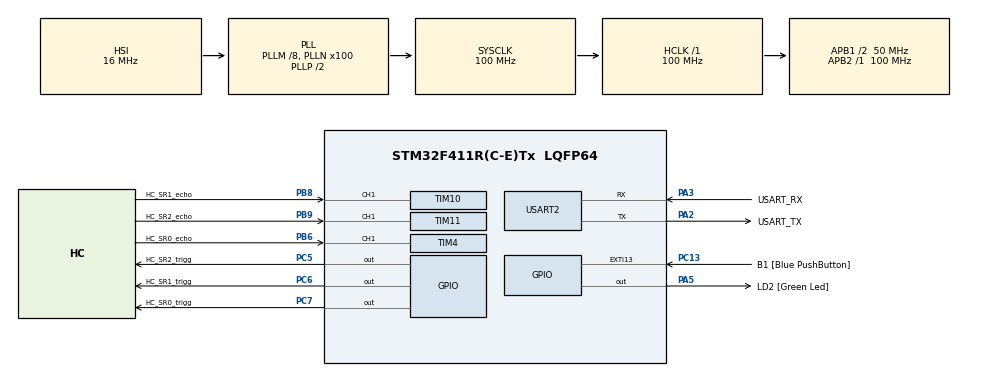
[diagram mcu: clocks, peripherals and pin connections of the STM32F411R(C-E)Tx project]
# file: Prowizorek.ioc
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Mcu.Family=STM32F4
Mcu.Name=STM32F411R(C-E)Tx
Mcu.Package=LQFP64
NVIC.PriorityGroup=NVIC_PRIORITYGROUP_0
PA13.GPIO_Label=TMS
PA13.Signal=SYS_JTMS-SWDIO
PA14.GPIO_Label=TCK
PA14.Signal=SYS_JTCK-SWCLK
PA2.GPIO_Label=USART_TX
PA2.Mode=Asynchronous
PA2.Signal=USART2_TX
PA3.GPIO_Label=USART_RX
PA3.Mode=Asynchronous
PA3.Signal=USART2_RX
PA5.GPIO_Label=LD2 [Green Led]
PA5.Signal=GPIO_Output
PB3.GPIO_Label=SWO
PB3.Signal=SYS_JTDO-SWO
PB6.GPIO_Label=HC_SR0_echo
PB6.Signal=S_TIM4_CH1
PB8.GPIO_Label=HC_SR1_echo
PB8.Signal=S_TIM10_CH1
PB9.GPIO_Label=HC_SR2_echo
PB9.Signal=S_TIM11_CH1
PC13-ANTI_TAMP.GPIO_Label=B1 [Blue PushButton]
PC13-ANTI_TAMP.GPIO_ModeDefaultEXTI=GPIO_MODE_EVT_RISING
PC13-ANTI_TAMP.Signal=GPXTI13
PC14-OSC32_IN.Signal=RCC_OSC32_IN
PC15-OSC32_OUT.Signal=RCC_OSC32_OUT
PC5.GPIO_Label=HC_SR2_trigg
PC5.GPIO_ModeDefaultOutputPP=GPIO_MODE_OUTPUT_OD
PC5.Signal=GPIO_Output
PC6.GPIO_Label=HC_SR1_trigg
PC6.GPIO_ModeDefaultOutputPP=GPIO_MODE_OUTPUT_OD
PC6.Signal=GPIO_Output
PC7.GPIO_Label=HC_SR0_trigg
PC7.GPIO_ModeDefaultOutputPP=GPIO_MODE_OUTPUT_OD
PC7.Signal=GPIO_Output
PH0\ -\ OSC_IN.Signal=RCC_OSC_IN
PH1\ -\ OSC_OUT.Signal=RCC_OSC_OUT
ProjectManager.HeapSize=0x400
ProjectManager.StackSize=0x200
ProjectManager.TargetToolchain=TrueSTUDIO
RCC.48MHZClocksFreq_Value=50000000
RCC.AHBFreq_Value=100000000
RCC.APB1CLKDivider=RCC_HCLK_DIV2
RCC.APB1Freq_Value=50000000
RCC.APB1TimFreq_Value=100000000
RCC.APB2Freq_Value=100000000
RCC.APB2TimFreq_Value=100000000
RCC.CortexFreq_Value=100000000
RCC.FLatency-AdvancedSettings=FLASH_LATENCY_2
RCC.HCLKFreq_Value=100000000
RCC.HSE_VALUE=8000000
RCC.HSI_VALUE=16000000
RCC.LSE_VALUE=32768
RCC.PLLM=8
RCC.PLLN=100
RCC.RCC_RTC_Clock_Source=RCC_RTCCLKSOURCE_LSI
RCC.SYSCLKFreq_VALUE=100000000
RCC.SYSCLKSource=RCC_SYSCLKSOURCE_PLLCLK
RCC.VCOOutputFreq_Value=200000000
SH.S_TIM10_CH1.0=TIM10_CH1,Input_Capture1_from_TI1
SH.S_TIM11_CH1.0=TIM11_CH1,Input_Capture1_from_TI1
SH.S_TIM4_CH1.0=TIM4_CH1,Input_Capture1_from_TI1
TIM10.Prescaler=100
TIM11.Prescaler=100
TIM4.Prescaler=100
VP_TIM10_VS_ClockSourceINT.Mode=Enable_Timer
VP_TIM11_VS_ClockSourceINT.Mode=Enable_Timer
board=NUCLEO-F411RE

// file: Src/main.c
/**
  ******************************************************************************
  * File Name          : main.c
  * Description        : Main program body
  ******************************************************************************
  *
  * COPYRIGHT(c) 2016 STMicroelectronics
  *
  * Redistribution and use in source and binary forms, with or without modification,
  * are permitted provided that the following conditions are met:
  *   1. Redistributions of source code must retain the above copyright notice,
  *      this list of conditions and the following disclaimer.
  *   2. Redistributions in binary form must reproduce the above copyright notice,
  *      this list of conditions and the following disclaimer in the documentation
  *      and/or other materials provided with the distribution.
  *   3. Neither the name of STMicroelectronics nor the names of its contributors
  *      may be used to endorse or promote products derived from this software
  *      without specific prior written permission.
  *
  * THIS SOFTWARE IS PROVIDED BY THE COPYRIGHT HOLDERS AND CONTRIBUTORS "AS IS"
  * AND ANY EXPRESS OR IMPLIED WARRANTIES, INCLUDING, BUT NOT LIMITED TO, THE
  * IMPLIED WARRANTIES OF MERCHANTABILITY AND FITNESS FOR A PARTICULAR PURPOSE ARE
  * DISCLAIMED. IN NO EVENT SHALL THE COPYRIGHT HOLDER OR CONTRIBUTORS BE LIABLE
  * FOR ANY DIRECT, INDIRECT, INCIDENTAL, SPECIAL, EXEMPLARY, OR CONSEQUENTIAL
  * DAMAGES (INCLUDING, BUT NOT LIMITED TO, PROCUREMENT OF SUBSTITUTE GOODS OR
  * SERVICES; LOSS OF USE, DATA, OR PROFITS; OR BUSINESS INTERRUPTION) HOWEVER
  * CAUSED AND ON ANY THEORY OF LIABILITY, WHETHER IN CONTRACT, STRICT LIABILITY,
  * OR TORT (INCLUDING NEGLIGENCE OR OTHERWISE) ARISING IN ANY WAY OUT OF THE USE
  * OF THIS SOFTWARE, EVEN IF ADVISED OF THE POSSIBILITY OF SUCH DAMAGE.
  *
  ******************************************************************************
  */
#include "stm32f4xx_hal.h"

TIM_HandleTypeDef htim4;
TIM_HandleTypeDef htim10;
TIM_HandleTypeDef htim11;

UART_HandleTypeDef huart2;

/* USER CODE BEGIN PV */
/* Private variables ---------------------------------------------------------*/

/* USER CODE END PV */

void SystemClock_Config(void);
static void MX_GPIO_Init(void);
static void MX_TIM4_Init(void);
static void MX_TIM10_Init(void);
static void MX_TIM11_Init(void);
static void MX_USART2_UART_Init(void);

/* USER CODE BEGIN PFP */
/* Private function prototypes -----------------------------------------------*/

/* USER CODE END PFP */

int main(void)
{

  /* MCU Configuration----------------------------------------------------------*/

  /* Reset of all peripherals, Initializes the Flash interface and the Systick. */
  HAL_Init();

  /* Configure the system clock */
  SystemClock_Config();

  /* Initialize all configured peripherals */
  MX_GPIO_Init();
  MX_TIM4_Init();
  MX_TIM10_Init();
  MX_TIM11_Init();
  MX_USART2_UART_Init();

  /* Infinite loop */
  while (1)
  {

  /* USER CODE BEGIN 3 */
	  HAL_Delay(250);
	  HAL_GPIO_TogglePin(LD2_GPIO_Port, LD2_Pin);

  }
  /* USER CODE END 3 */

}

/** System Clock Configuration
*/
void SystemClock_Config(void)
{

  RCC_OscInitTypeDef RCC_OscInitStruct;
  RCC_ClkInitTypeDef RCC_ClkInitStruct;

  __PWR_CLK_ENABLE();

  __HAL_PWR_VOLTAGESCALING_CONFIG(PWR_REGULATOR_VOLTAGE_SCALE1);

  RCC_OscInitStruct.OscillatorType = RCC_OSCILLATORTYPE_HSI;
  RCC_OscInitStruct.HSIState = RCC_HSI_ON;
  RCC_OscInitStruct.HSICalibrationValue = 16;
  RCC_OscInitStruct.PLL.PLLState = RCC_PLL_ON;
  RCC_OscInitStruct.PLL.PLLSource = RCC_PLLSOURCE_HSI;
  RCC_OscInitStruct.PLL.PLLM = 8;
  RCC_OscInitStruct.PLL.PLLN = 100;
  RCC_OscInitStruct.PLL.PLLP = RCC_PLLP_DIV2;
  RCC_OscInitStruct.PLL.PLLQ = 4;
  HAL_RCC_OscConfig(&RCC_OscInitStruct);

  RCC_ClkInitStruct.ClockType = RCC_CLOCKTYPE_HCLK|RCC_CLOCKTYPE_SYSCLK
                              |RCC_CLOCKTYPE_PCLK1|RCC_CLOCKTYPE_PCLK2;
  RCC_ClkInitStruct.SYSCLKSource = RCC_SYSCLKSOURCE_PLLCLK;
  RCC_ClkInitStruct.AHBCLKDivider = RCC_SYSCLK_DIV1;
  RCC_ClkInitStruct.APB1CLKDivider = RCC_HCLK_DIV2;
  RCC_ClkInitStruct.APB2CLKDivider = RCC_HCLK_DIV1;
  HAL_RCC_ClockConfig(&RCC_ClkInitStruct, FLASH_LATENCY_2);

  HAL_SYSTICK_Config(HAL_RCC_GetHCLKFreq()/1000);

  HAL_SYSTICK_CLKSourceConfig(SYSTICK_CLKSOURCE_HCLK);

  /* SysTick_IRQn interrupt configuration */
  HAL_NVIC_SetPriority(SysTick_IRQn, 0, 0);
}

/* TIM4 init function */
void MX_TIM4_Init(void)
{

  TIM_MasterConfigTypeDef sMasterConfig;
  TIM_IC_InitTypeDef sConfigIC;

  htim4.Instance = TIM4;
  htim4.Init.Prescaler = 100;
  htim4.Init.CounterMode = TIM_COUNTERMODE_UP;
  htim4.Init.Period = 0;
  htim4.Init.ClockDivision = TIM_CLOCKDIVISION_DIV1;
  HAL_TIM_IC_Init(&htim4);

  sMasterConfig.MasterOutputTrigger = TIM_TRGO_RESET;
  sMasterConfig.MasterSlaveMode = TIM_MASTERSLAVEMODE_DISABLE;
  HAL_TIMEx_MasterConfigSynchronization(&htim4, &sMasterConfig);

  sConfigIC.ICPolarity = TIM_INPUTCHANNELPOLARITY_RISING;
  sConfigIC.ICSelection = TIM_ICSELECTION_DIRECTTI;
  sConfigIC.ICPrescaler = TIM_ICPSC_DIV1;
  sConfigIC.ICFilter = 0;
  HAL_TIM_IC_ConfigChannel(&htim4, &sConfigIC, TIM_CHANNEL_1);

}

/* TIM10 init function */
void MX_TIM10_Init(void)
{

  TIM_IC_InitTypeDef sConfigIC;

  htim10.Instance = TIM10;
  htim10.Init.Prescaler = 100;
  htim10.Init.CounterMode = TIM_COUNTERMODE_UP;
  htim10.Init.Period = 0;
  htim10.Init.ClockDivision = TIM_CLOCKDIVISION_DIV1;
  HAL_TIM_Base_Init(&htim10);

  HAL_TIM_IC_Init(&htim10);

  sConfigIC.ICPolarity = TIM_INPUTCHANNELPOLARITY_RISING;
  sConfigIC.ICSelection = TIM_ICSELECTION_DIRECTTI;
  sConfigIC.ICPrescaler = TIM_ICPSC_DIV1;
  sConfigIC.ICFilter = 0;
  HAL_TIM_IC_ConfigChannel(&htim10, &sConfigIC, TIM_CHANNEL_1);

}

/* TIM11 init function */
void MX_TIM11_Init(void)
{

  TIM_IC_InitTypeDef sConfigIC;

  htim11.Instance = TIM11;
  htim11.Init.Prescaler = 100;
  htim11.Init.CounterMode = TIM_COUNTERMODE_UP;
  htim11.Init.Period = 0;
  htim11.Init.ClockDivision = TIM_CLOCKDIVISION_DIV1;
  HAL_TIM_Base_Init(&htim11);

  HAL_TIM_IC_Init(&htim11);

  sConfigIC.ICPolarity = TIM_INPUTCHANNELPOLARITY_RISING;
  sConfigIC.ICSelection = TIM_ICSELECTION_DIRECTTI;
  sConfigIC.ICPrescaler = TIM_ICPSC_DIV1;
  sConfigIC.ICFilter = 0;
  HAL_TIM_IC_ConfigChannel(&htim11, &sConfigIC, TIM_CHANNEL_1);

}

/* USART2 init function */
void MX_USART2_UART_Init(void)
{

  huart2.Instance = USART2;
  huart2.Init.BaudRate = 115200;
  huart2.Init.WordLength = UART_WORDLENGTH_8B;
  huart2.Init.StopBits = UART_STOPBITS_1;
  huart2.Init.Parity = UART_PARITY_NONE;
  huart2.Init.Mode = UART_MODE_TX_RX;
  huart2.Init.HwFlowCtl = UART_HWCONTROL_NONE;
  huart2.Init.OverSampling = UART_OVERSAMPLING_16;
  HAL_UART_Init(&huart2);

}

/** Configure pins as
        * Analog
        * Input
        * Output
        * EVENT_OUT
        * EXTI
*/
void MX_GPIO_Init(void)
{

  GPIO_InitTypeDef GPIO_InitStruct;

  /* GPIO Ports Clock Enable */
  __GPIOC_CLK_ENABLE();
  __GPIOH_CLK_ENABLE();
  __GPIOA_CLK_ENABLE();
  __GPIOB_CLK_ENABLE();

  /*Configure GPIO pin : B1_Pin */
  GPIO_InitStruct.Pin = B1_Pin;
  GPIO_InitStruct.Mode = GPIO_MODE_EVT_RISING;
  GPIO_InitStruct.Pull = GPIO_NOPULL;
  HAL_GPIO_Init(B1_GPIO_Port, &GPIO_InitStruct);

  /*Configure GPIO pin : LD2_Pin */
  GPIO_InitStruct.Pin = LD2_Pin;
  GPIO_InitStruct.Mode = GPIO_MODE_OUTPUT_PP;
  GPIO_InitStruct.Pull = GPIO_NOPULL;
  GPIO_InitStruct.Speed = GPIO_SPEED_LOW;
  HAL_GPIO_Init(LD2_GPIO_Port, &GPIO_InitStruct);

  /*Configure GPIO pins : HC_SR2_trigg_Pin HC_SR1_trigg_Pin HC_SR0_trigg_Pin */
  GPIO_InitStruct.Pin = HC_SR2_trigg_Pin|HC_SR1_trigg_Pin|HC_SR0_trigg_Pin;
  GPIO_InitStruct.Mode = GPIO_MODE_OUTPUT_OD;
  GPIO_InitStruct.Pull = GPIO_NOPULL;
  GPIO_InitStruct.Speed = GPIO_SPEED_LOW;
  HAL_GPIO_Init(GPIOC, &GPIO_InitStruct);

  /*Configure GPIO pin Output Level */
  HAL_GPIO_WritePin(LD2_GPIO_Port, LD2_Pin, GPIO_PIN_RESET);

  /*Configure GPIO pin Output Level */
  HAL_GPIO_WritePin(GPIOC, HC_SR2_trigg_Pin|HC_SR1_trigg_Pin|HC_SR0_trigg_Pin, GPIO_PIN_RESET);

}

/************************ (C) COPYRIGHT STMicroelectronics *****END OF FILE****/
